VERSION ""

NS_ :

BS_:

BU_: DAS DAS DAS CONTROL STEER DAS DAS TELEMETRY TLM DAS TLM STEER STEER IMU TLM DAS IMU

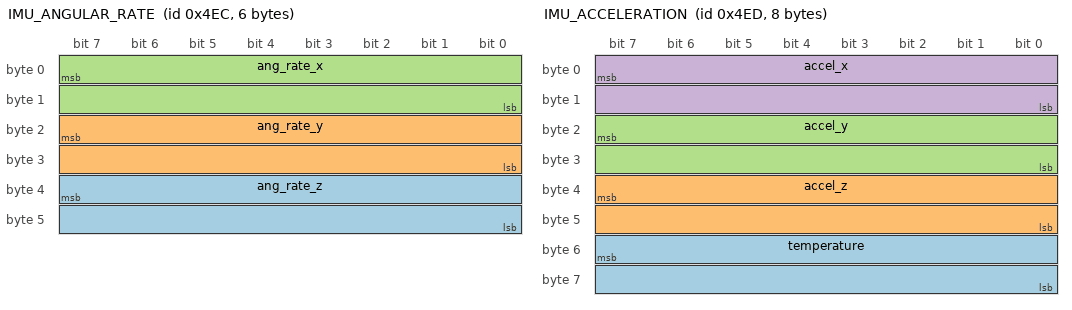
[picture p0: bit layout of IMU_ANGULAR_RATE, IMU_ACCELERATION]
BO_ 1260 IMU_ANGULAR_RATE: 6 Vector__XXX
 SG_ ang_rate_z : 39|16@0+ (0.007476920729381247,-245) [-245|245] "" Vector__XXX
 SG_ ang_rate_y : 23|16@0+ (0.007476920729381247,-245) [-245|245] "" Vector__XXX
 SG_ ang_rate_x : 7|16@0+ (0.007476920729381247,-245) [-245|245] "" Vector__XXX

BO_ 1261 IMU_ACCELERATION: 8 Vector__XXX
 SG_ temperature : 55|16@0- (1,-32768) [-32768|32767] "" Vector__XXX
 SG_ accel_z : 39|16@0+ (0.00024414435034714275,-8) [-8|8] "" Vector__XXX
 SG_ accel_y : 23|16@0+ (0.00024414435034714275,-8) [-8|8] "" Vector__XXX
 SG_ accel_x : 7|16@0+ (0.00024414435034714275,-8) [-8|8] "" Vector__XXX

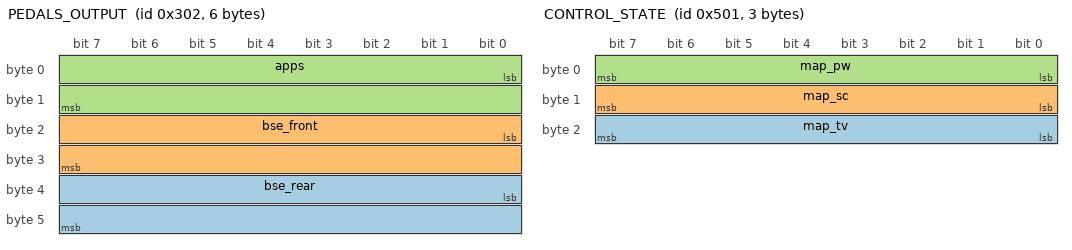
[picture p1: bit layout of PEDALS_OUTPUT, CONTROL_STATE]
BO_ 770 PEDALS_OUTPUT: 6 Vector__XXX
 SG_ bse_rear : 32|16@1+ (0.0015259021896696422,0) [0|100] "" Vector__XXX
 SG_ bse_front : 16|16@1+ (0.0015259021896696422,0) [0|100] "" Vector__XXX
 SG_ apps : 0|16@1+ (0.0015259021896696422,0) [0|100] "" Vector__XXX

BO_ 259 STEERING_ANGLE: 4 Vector__XXX
 SG_ angle : 0|32@1+ (1.676380634698174e-07,-360) [-360|360] "" Vector__XXX

BO_ 1281 CONTROL_STATE: 3 Vector__XXX
 SG_ map_tv : 16|8@1+ (0.01,0) [0|1] "" Vector__XXX
 SG_ map_sc : 8|8@1+ (0.01,0) [0|1] "" Vector__XXX
 SG_ map_pw : 0|8@1+ (0.01,-0.5) [-0.5|1] "" Vector__XXX

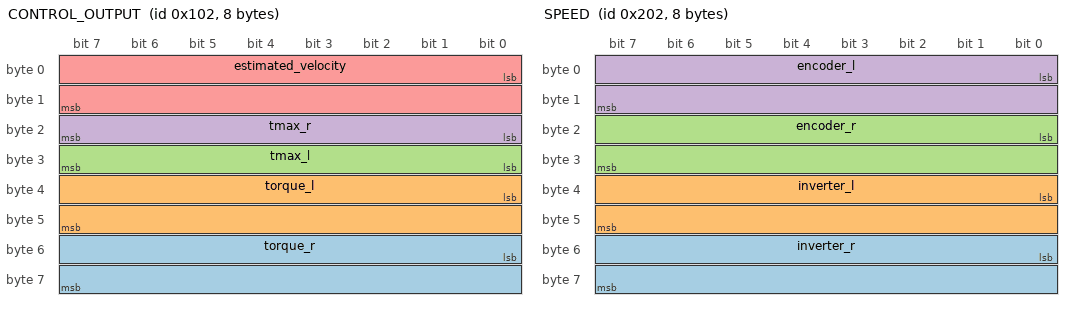
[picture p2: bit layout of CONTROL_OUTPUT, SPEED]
BO_ 258 CONTROL_OUTPUT: 8 Vector__XXX
 SG_ torque_r : 48|16@1+ (0.0012207217517357137,0) [0|80] "" Vector__XXX
 SG_ torque_l : 32|16@1+ (0.0012207217517357137,0) [0|80] "" Vector__XXX
 SG_ tmax_l : 24|8@1+ (0.3137254901960784,0) [0|80] "" Vector__XXX
 SG_ tmax_r : 16|8@1+ (0.3137254901960784,0) [0|80] "" Vector__XXX
 SG_ estimated_velocity : 0|16@1+ (0.0009155413138017853,-10) [-10|50] "" Vector__XXX

BO_ 514 SPEED: 8 Vector__XXX
 SG_ inverter_r : 48|16@1+ (0.003356984817273213,-20) [-20|200] "" Vector__XXX
 SG_ inverter_l : 32|16@1+ (0.003356984817273213,-20) [-20|200] "" Vector__XXX
 SG_ encoder_r : 16|16@1+ (0.003356984817273213,-20) [-20|200] "" Vector__XXX
 SG_ encoder_l : 0|16@1+ (0.003356984817273213,-20) [-20|200] "" Vector__XXX

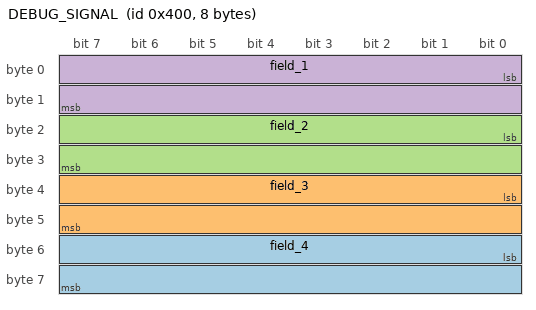
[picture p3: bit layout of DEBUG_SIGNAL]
BO_ 1024 DEBUG_SIGNAL: 8 Vector__XXX
 SG_ field_4 : 48|16@1+ (3.0518043793392844e-05,-1) [-1|1] "" Vector__XXX
 SG_ field_3 : 32|16@1+ (3.0518043793392844e-05,-1) [-1|1] "" Vector__XXX
 SG_ field_2 : 16|16@1+ (3.0518043793392844e-05,-1) [-1|1] "" Vector__XXX
 SG_ field_1 : 0|16@1+ (3.0518043793392844e-05,-1) [-1|1] "" Vector__XXX

CM_ BO_ 1260 "Inertial Measurement Unit [x,y,z]-axis angular rate value. 0.01dps per bit, Big-Endian, 16bit Total, signed";
CM_ BO_ 1261 "Inertial Measurement Unit [x,y,z]-axis acceleration value. 0.01g per bit, Big-Endian, 16bit Total, signed";
CM_ BO_ 770 "Pedal output, already calibrated";
CM_ BO_ 259 "Steering angle in degrees";
CM_ BO_ 1281 "Send status of traction control";
CM_ BO_ 258 "Control output, N*m";
CM_ BO_ 514 "Encoder and inverter speed in rad/s";
CM_ BO_ 1024 "Debug signals";
BA_DEF_ BO_  "GenMsgCycleTime" INT 0 65535;
BA_DEF_DEF_  "GenMsgCycleTime" 0;
BA_ "GenMsgCycleTime" BO_ 770 10;
BA_ "GenMsgCycleTime" BO_ 259 10;
BA_ "GenMsgCycleTime" BO_ 1281 100;
BA_ "GenMsgCycleTime" BO_ 258 100;
BA_ "GenMsgCycleTime" BO_ 514 10;
BA_ "GenMsgCycleTime" BO_ 1024 10;
